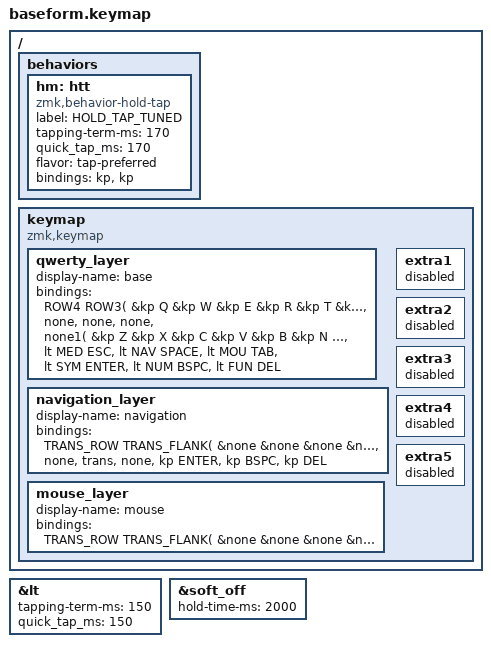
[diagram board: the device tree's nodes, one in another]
#include <behaviors.dtsi>
#include <dt-bindings/zmk/keys.h>
#include <dt-bindings/zmk/bt.h>
#include <dt-bindings/zmk/ext_power.h>
#include <dt-bindings/zmk/outputs.h>
#include "../keymap_edges.dtsi"

// Mouse movement settings
#define ZMK_POINTING_DEFAULT_MOVE_VAL 3000
#define ZMK_MOUSE_DEFAULT_MOVE_VAL 3000

#define QWE 0
#define NAV 1
#define MOU 2
#define BUT 3
#define MED 4
#define SYM 5
#define FUN 6

&lt {
  tapping-term-ms = <150>;
  quick_tap_ms = <150>;
};

&soft_off {
    hold-time-ms = <2000>; 
};

/ {

  behaviors {
    hm: htt {
      compatible = "zmk,behavior-hold-tap";
      label = "HOLD_TAP_TUNED";
      #binding-cells = <2>;
      tapping-term-ms = <170>;
      quick_tap_ms = <170>;
      flavor = "tap-preferred";
      bindings = <&kp>, <&kp>;
    };
  };

  keymap {
    compatible = "zmk,keymap";

    qwerty_layer {
      display-name = "base";
      bindings = <
        ROW4
        ROW3( &kp Q       &kp W       &kp E        &kp R        &kp T    &kp Y  &kp U          &kp I         &kp O         &kp P          )
        ROW2( &hm LGUI A  &hm LALT S  &hm LCTRL D  &hm LSHFT F  &kp G    &kp H  &hm RSHIFT J   &hm RCTRL K   &hm  RALT L   &hm RGUI APOS  )
        ROW&none    &none    &none     &none     &none1( &kp Z       &kp X       &kp C        &kp V        &kp B    &kp N  &kp M          &kp COMMA     &kp DOT       &kp COLON      )
                                &lt MED ESC &lt NAV SPACE &lt MOU TAB    &lt SYM ENTER &lt NUM BSPC &lt FUN DEL
      >;
    };
  
  navigation_layer {
    display-name = "navigation";
    bindings = <
      TRANS_ROW
      TRANS_FLANK( &none    &none    &none     &none     &none     &kp K_REDO &kp K_PASTE &kp K_COPY &kp K_CUT &kp K_UNDO )
      TRANS_FLANK( &kp LGUI &kp LALT &kp LCTRL &kp LSHFT &none     &kp CAPS   &kp LEFT    &kp DOWN   &kp UP    &kp RIGHT  )
      TRANS_FLANK( &none    &none    &none     &none     &none     &kp INS    &kp HOME    &kp PG_DN  &kp PG_UP &kp END    )
                            &none    &trans    &none     &kp ENTER &kp BSPC   &kp DEL
    >;
  };

  mouse_layer {
    display-name = "mouse";
    bindings = <
      TRANS_ROW
      TRANS_FLANK( &none    &none    &none     &none     &none     &kp K_REDO &kp K_PASTE &kp K_COPY &kp K_CUT &kp K_UNDO )
      TRANS_FLANK(      &none      &mmv MOVE_LEFT &mmv MOVE_DOWN &mmv MOVE_UP &mmv MOVE_RIGHT )
      TRANS_FLANK( )
    >;
  };

 
#include "../shared_layers.dtsi"

    extra1 {
        status = "reserved";
    };

    extra2 {
        status = "reserved";
    };

    extra3 {
        status = "reserved";
    };

    extra4 {
        status = "reserved";
    };

    extra5 {
        status = "reserved";
    };


  };
};
